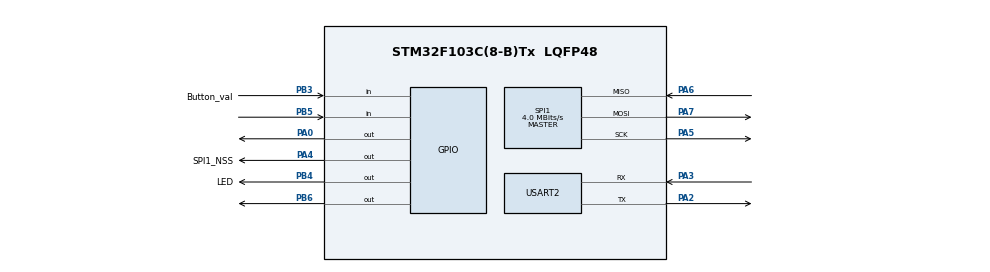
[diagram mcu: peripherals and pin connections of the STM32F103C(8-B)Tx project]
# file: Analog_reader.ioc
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Mcu.Family=STM32F1
Mcu.Name=STM32F103C(8-B)Tx
Mcu.Package=LQFP48
NVIC.PriorityGroup=NVIC_PRIORITYGROUP_4
NVIC.SPI1_IRQn=true\:0\:0\:false\:false\:true\:true\:true
PA0-WKUP.Signal=GPIO_Output
PA13.Mode=Serial_Wire
PA13.Signal=SYS_JTMS-SWDIO
PA14.Mode=Serial_Wire
PA14.Signal=SYS_JTCK-SWCLK
PA2.Mode=Asynchronous
PA2.Signal=USART2_TX
PA3.Mode=Asynchronous
PA3.Signal=USART2_RX
PA4.GPIO_Label=SPI1_NSS
PA4.Signal=GPIO_Output
PA5.Mode=Full_Duplex_Master
PA5.Signal=SPI1_SCK
PA6.Mode=Full_Duplex_Master
PA6.Signal=SPI1_MISO
PA7.Mode=Full_Duplex_Master
PA7.Signal=SPI1_MOSI
PB3.GPIO_Label=Button_val
PB3.Signal=GPIO_Input
PB4.GPIO_Label=LED
PB4.Signal=GPIO_Output
PB5.Signal=GPIO_Input
PB6.Signal=GPIO_Output
PC14-OSC32_IN.Mode=LSE-External-Oscillator
PC14-OSC32_IN.Signal=RCC_OSC32_IN
PC15-OSC32_OUT.Mode=LSE-External-Oscillator
PC15-OSC32_OUT.Signal=RCC_OSC32_OUT
PD0-OSC_IN.Mode=HSE-External-Oscillator
PD0-OSC_IN.Signal=RCC_OSC_IN
PD1-OSC_OUT.Mode=HSE-External-Oscillator
PD1-OSC_OUT.Signal=RCC_OSC_OUT
ProjectManager.HeapSize=0x200
ProjectManager.StackSize=0x400
ProjectManager.TargetToolchain=STM32CubeIDE
RCC.APB1Freq_Value=8000000
RCC.APB2Freq_Value=8000000
RCC.HSE_VALUE=16000000
SPI1.CalculateBaudRate=4.0 MBits/s
SPI1.Direction=SPI_DIRECTION_2LINES
SPI1.Mode=SPI_MODE_MASTER
SPI1.VirtualType=VM_MASTER
USART2.VirtualMode=VM_ASYNC
board=custom

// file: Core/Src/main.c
/* USER CODE BEGIN Header */
/**
  ******************************************************************************
  * @file           : main.c
  * @brief          : Main program for testing the main controller
  * @author 		: Chathura Jayasankha Gamage
  ******************************************************************************
  * @attention
  *
  * <h2><center>&copy; Copyright (c) 2022 STMicroelectronics.
  * All rights reserved.</center></h2>
  *
  * This software component is licensed by ST under BSD 3-Clause license,
  * the "License"; You may not use this file except in compliance with the
  * License. You may obtain a copy of the License at:
  *                        opensource.org/licenses/BSD-3-Clause
  *
  ******************************************************************************
  */
/* USER CODE END Header */
#include "main.h"

SPI_HandleTypeDef hspi1;

UART_HandleTypeDef huart2;

/* USER CODE BEGIN PV */
int sample_counter = 0;
char msg[10];
char uart_buf[100];
int uart_buf_len;
/* USER CODE END PV */

void SystemClock_Config(void);
static void MX_GPIO_Init(void);
static void MX_SPI1_Init(void);
static void MX_USART2_UART_Init(void);

int main(void)
{

  /* MCU Configuration--------------------------------------------------------*/

  /* Reset of all peripherals, Initializes the Flash interface and the Systick. */
  HAL_Init();

  /* Configure the system clock */
  SystemClock_Config();

  /* Initialize all configured peripherals */
  MX_GPIO_Init();
  MX_SPI1_Init();
  MX_USART2_UART_Init();
  /* USER CODE BEGIN 2 */

  uart_buf_len = sprintf(uart_buf, "Timer starting ...\r\n");
  HAL_UART_Transmit(&huart2, (uint8_t *)uart_buf, uart_buf_len, 100);
  HAL_Delay(500);

  HAL_GPIO_WritePin(GPIOA, GPIO_PIN_0, GPIO_PIN_SET);

  /* USER CODE END 2 */

  /* Infinite loop */
  while (1)
  {

    /* USER CODE BEGIN 3 */
	  sample_counter++;
	  sprintf(msg, "counter %hu\r\n", sample_counter);
	  HAL_UART_Transmit(&huart2, (uint8_t*)msg, strlen(msg), HAL_MAX_DELAY);

	  HAL_GPIO_TogglePin(GPIOA, GPIO_PIN_0);
	  HAL_Delay(1000);

  }
  /* USER CODE END 3 */
}

void SystemClock_Config(void)
{
  RCC_OscInitTypeDef RCC_OscInitStruct = {0};
  RCC_ClkInitTypeDef RCC_ClkInitStruct = {0};

  /** Initializes the RCC Oscillators according to the specified parameters
  * in the RCC_OscInitTypeDef structure.
  */
  RCC_OscInitStruct.OscillatorType = RCC_OSCILLATORTYPE_HSI;
  RCC_OscInitStruct.HSIState = RCC_HSI_ON;
  RCC_OscInitStruct.HSICalibrationValue = RCC_HSICALIBRATION_DEFAULT;
  RCC_OscInitStruct.PLL.PLLState = RCC_PLL_NONE;
  if (HAL_RCC_OscConfig(&RCC_OscInitStruct) != HAL_OK)
  {
    Error_Handler();
  }
  /** Initializes the CPU, AHB and APB buses clocks
  */
  RCC_ClkInitStruct.ClockType = RCC_CLOCKTYPE_HCLK|RCC_CLOCKTYPE_SYSCLK
                              |RCC_CLOCKTYPE_PCLK1|RCC_CLOCKTYPE_PCLK2;
  RCC_ClkInitStruct.SYSCLKSource = RCC_SYSCLKSOURCE_HSI;
  RCC_ClkInitStruct.AHBCLKDivider = RCC_SYSCLK_DIV1;
  RCC_ClkInitStruct.APB1CLKDivider = RCC_HCLK_DIV1;
  RCC_ClkInitStruct.APB2CLKDivider = RCC_HCLK_DIV1;

  if (HAL_RCC_ClockConfig(&RCC_ClkInitStruct, FLASH_LATENCY_0) != HAL_OK)
  {
    Error_Handler();
  }
}

static void MX_SPI1_Init(void)
{

  /* SPI1 parameter configuration*/
  hspi1.Instance = SPI1;
  hspi1.Init.Mode = SPI_MODE_MASTER;
  hspi1.Init.Direction = SPI_DIRECTION_2LINES;
  hspi1.Init.DataSize = SPI_DATASIZE_8BIT;
  hspi1.Init.CLKPolarity = SPI_POLARITY_LOW;
  hspi1.Init.CLKPhase = SPI_PHASE_1EDGE;
  hspi1.Init.NSS = SPI_NSS_SOFT;
  hspi1.Init.BaudRatePrescaler = SPI_BAUDRATEPRESCALER_2;
  hspi1.Init.FirstBit = SPI_FIRSTBIT_MSB;
  hspi1.Init.TIMode = SPI_TIMODE_DISABLE;
  hspi1.Init.CRCCalculation = SPI_CRCCALCULATION_DISABLE;
  hspi1.Init.CRCPolynomial = 10;
  if (HAL_SPI_Init(&hspi1) != HAL_OK)
  {
    Error_Handler();
  }

}

static void MX_USART2_UART_Init(void)
{

  huart2.Instance = USART2;
  huart2.Init.BaudRate = 115200;
  huart2.Init.WordLength = UART_WORDLENGTH_8B;
  huart2.Init.StopBits = UART_STOPBITS_1;
  huart2.Init.Parity = UART_PARITY_NONE;
  huart2.Init.Mode = UART_MODE_TX_RX;
  huart2.Init.HwFlowCtl = UART_HWCONTROL_NONE;
  huart2.Init.OverSampling = UART_OVERSAMPLING_16;
  if (HAL_UART_Init(&huart2) != HAL_OK)
  {
    Error_Handler();
  }

}

static void MX_GPIO_Init(void)
{
  GPIO_InitTypeDef GPIO_InitStruct = {0};

  /* GPIO Ports Clock Enable */
  __HAL_RCC_GPIOC_CLK_ENABLE();
  __HAL_RCC_GPIOD_CLK_ENABLE();
  __HAL_RCC_GPIOA_CLK_ENABLE();
  __HAL_RCC_GPIOB_CLK_ENABLE();

  /*Configure GPIO pin Output Level */
  HAL_GPIO_WritePin(GPIOA, GPIO_PIN_0|SPI1_NSS_Pin, GPIO_PIN_RESET);

  /*Configure GPIO pin Output Level */
  HAL_GPIO_WritePin(GPIOB, LED_Pin|GPIO_PIN_6, GPIO_PIN_RESET);

  /*Configure GPIO pins : PA0 SPI1_NSS_Pin */
  GPIO_InitStruct.Pin = GPIO_PIN_0|SPI1_NSS_Pin;
  GPIO_InitStruct.Mode = GPIO_MODE_OUTPUT_PP;
  GPIO_InitStruct.Pull = GPIO_NOPULL;
  GPIO_InitStruct.Speed = GPIO_SPEED_FREQ_LOW;
  HAL_GPIO_Init(GPIOA, &GPIO_InitStruct);

  /*Configure GPIO pins : Button_val_Pin PB5 */
  GPIO_InitStruct.Pin = Button_val_Pin|GPIO_PIN_5;
  GPIO_InitStruct.Mode = GPIO_MODE_INPUT;
  GPIO_InitStruct.Pull = GPIO_NOPULL;
  HAL_GPIO_Init(GPIOB, &GPIO_InitStruct);

  /*Configure GPIO pins : LED_Pin PB6 */
  GPIO_InitStruct.Pin = LED_Pin|GPIO_PIN_6;
  GPIO_InitStruct.Mode = GPIO_MODE_OUTPUT_PP;
  GPIO_InitStruct.Pull = GPIO_NOPULL;
  GPIO_InitStruct.Speed = GPIO_SPEED_FREQ_LOW;
  HAL_GPIO_Init(GPIOB, &GPIO_InitStruct);

}

void Error_Handler(void)
{
  __disable_irq();
  while (1)
  {
  }
}

/************************ (C) COPYRIGHT STMicroelectronics *****END OF FILE****/
